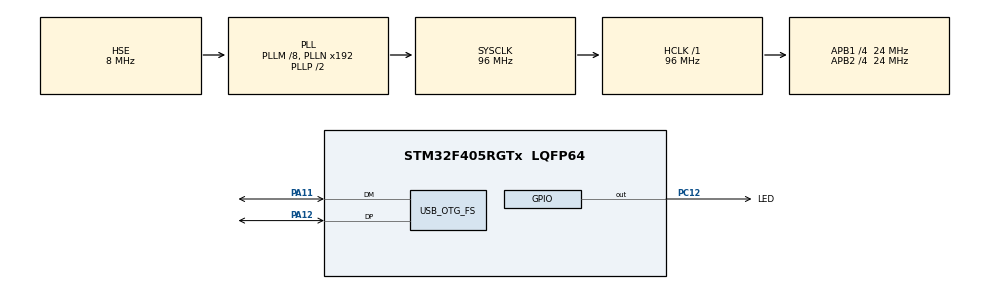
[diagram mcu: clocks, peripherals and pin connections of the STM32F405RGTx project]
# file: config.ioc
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IWDG.Prescaler=IWDG_PRESCALER_32
Mcu.Family=STM32F4
Mcu.Name=STM32F405RGTx
Mcu.Package=LQFP64
NVIC.OTG_FS_IRQn=true\:0\:0\:false
NVIC.PriorityGroup=NVIC_PRIORITYGROUP_4
PA11.Mode=Device_Only
PA11.Signal=USB_OTG_FS_DM
PA12.Mode=Device_Only
PA12.Signal=USB_OTG_FS_DP
PC12.GPIO_Label=LED
PC12.GPIO_ModeDefaultOutputPP=GPIO_MODE_OUTPUT_OD
PC12.GPIO_PuPd=GPIO_NOPULL
PC12.GPIO_Speed=GPIO_SPEED_LOW
PC12.Signal=GPIO_Output
PC14-OSC32_IN.Mode=LSE-External-Oscillator
PC14-OSC32_IN.Signal=RCC_OSC32_IN
PC15-OSC32_OUT.Mode=LSE-External-Oscillator
PC15-OSC32_OUT.Signal=RCC_OSC32_OUT
PH0-OSC_IN.Mode=HSE-External-Oscillator
PH0-OSC_IN.Signal=RCC_OSC_IN
PH1-OSC_OUT.Mode=HSE-External-Oscillator
PH1-OSC_OUT.Signal=RCC_OSC_OUT
ProjectManager.TargetToolchain=EWARM
RCC.48MHZClocksFreq_Value=48000000
RCC.AHBFreq_Value=96000000
RCC.APB1CLKDivider=RCC_HCLK_DIV4
RCC.APB1Freq_Value=24000000
RCC.APB1TimFreq_Value=48000000
RCC.APB2CLKDivider=RCC_HCLK_DIV4
RCC.APB2Freq_Value=24000000
RCC.APB2TimFreq_Value=48000000
RCC.CortexFreq_Value=96000000
RCC.HCLKFreq_Value=96000000
RCC.HSE_VALUE=8000000
RCC.HSI_VALUE=16000000
RCC.PLLM=8
RCC.SYSCLKFreq_VALUE=96000000
RCC.SYSCLKSource=RCC_SYSCLKSOURCE_PLLCLK
RCC.VCOOutputFreq_Value=192000000
USB_DEVICE.CLASS_NAME-CDC_FS=CDC
USB_DEVICE.USBD_HandleTypeDef-CDC_FS=hUsbDeviceFS
USB_DEVICE.VirtualMode-CDC_FS=Cdc
USB_DEVICE.VirtualModeFS=Cdc_FS
USB_OTG_FS.VirtualMode=Device_Only
USB_OTG_FS.vbus_sensing_enable=DISABLE
VP_IWDG_VS_IWDG.Mode=IWDG_Activate
VP_USB_DEVICE_VS_USB_DEVICE_CDC_FS.Mode=CDC_FS

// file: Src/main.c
/**
  ******************************************************************************
  * File Name          : main.c
  * Description        : Main program body
  ******************************************************************************
  *
  * COPYRIGHT(c) 2015 STMicroelectronics
  *
  * Redistribution and use in source and binary forms, with or without modification,
  * are permitted provided that the following conditions are met:
  *   1. Redistributions of source code must retain the above copyright notice,
  *      this list of conditions and the following disclaimer.
  *   2. Redistributions in binary form must reproduce the above copyright notice,
  *      this list of conditions and the following disclaimer in the documentation
  *      and/or other materials provided with the distribution.
  *   3. Neither the name of STMicroelectronics nor the names of its contributors
  *      may be used to endorse or promote products derived from this software
  *      without specific prior written permission.
  *
  * THIS SOFTWARE IS PROVIDED BY THE COPYRIGHT HOLDERS AND CONTRIBUTORS "AS IS"
  * AND ANY EXPRESS OR IMPLIED WARRANTIES, INCLUDING, BUT NOT LIMITED TO, THE
  * IMPLIED WARRANTIES OF MERCHANTABILITY AND FITNESS FOR A PARTICULAR PURPOSE ARE
  * DISCLAIMED. IN NO EVENT SHALL THE COPYRIGHT HOLDER OR CONTRIBUTORS BE LIABLE
  * FOR ANY DIRECT, INDIRECT, INCIDENTAL, SPECIAL, EXEMPLARY, OR CONSEQUENTIAL
  * DAMAGES (INCLUDING, BUT NOT LIMITED TO, PROCUREMENT OF SUBSTITUTE GOODS OR
  * SERVICES; LOSS OF USE, DATA, OR PROFITS; OR BUSINESS INTERRUPTION) HOWEVER
  * CAUSED AND ON ANY THEORY OF LIABILITY, WHETHER IN CONTRACT, STRICT LIABILITY,
  * OR TORT (INCLUDING NEGLIGENCE OR OTHERWISE) ARISING IN ANY WAY OUT OF THE USE
  * OF THIS SOFTWARE, EVEN IF ADVISED OF THE POSSIBILITY OF SUCH DAMAGE.
  *
  ******************************************************************************
  */

#include "stm32f4xx_hal.h"
#include "usb_device.h"

/* USER CODE BEGIN Includes */
#include "main.h"
#include "cli.h"
#include "config.h"
/* USER CODE END Includes */

IWDG_HandleTypeDef hiwdg;

void SystemClock_Config(void);
static void MX_GPIO_Init(void);
static void MX_IWDG_Init(void);

int main(void)
{

  /* MCU Configuration----------------------------------------------------------*/

  /* Reset of all peripherals, Initializes the Flash interface and the Systick. */
  HAL_Init();

  /* Configure the system clock */
  SystemClock_Config();

  /* Initialize all configured peripherals */
  MX_GPIO_Init();
  MX_IWDG_Init();
  MX_USB_DEVICE_Init();

  /* USER CODE BEGIN 2 */
	cfg_init();
  /* USER CODE END 2 */

  /* Infinite loop */
  while (1)
  {

  /* USER CODE BEGIN 3 */
    cli_run();

  }
  /* USER CODE END 3 */

}

/** System Clock Configuration
*/
void SystemClock_Config(void)
{

  RCC_OscInitTypeDef RCC_OscInitStruct;
  RCC_ClkInitTypeDef RCC_ClkInitStruct;

  __PWR_CLK_ENABLE();

  __HAL_PWR_VOLTAGESCALING_CONFIG(PWR_REGULATOR_VOLTAGE_SCALE2);

  RCC_OscInitStruct.OscillatorType = RCC_OSCILLATORTYPE_LSI|RCC_OSCILLATORTYPE_HSE;
  RCC_OscInitStruct.HSEState = RCC_HSE_ON;
  RCC_OscInitStruct.LSIState = RCC_LSI_ON;
  RCC_OscInitStruct.PLL.PLLState = RCC_PLL_ON;
  RCC_OscInitStruct.PLL.PLLSource = RCC_PLLSOURCE_HSE;
  RCC_OscInitStruct.PLL.PLLM = 8;
  RCC_OscInitStruct.PLL.PLLN = 192;
  RCC_OscInitStruct.PLL.PLLP = RCC_PLLP_DIV2;
  RCC_OscInitStruct.PLL.PLLQ = 4;
  HAL_RCC_OscConfig(&RCC_OscInitStruct);

  RCC_ClkInitStruct.ClockType = RCC_CLOCKTYPE_SYSCLK|RCC_CLOCKTYPE_PCLK1
                              |RCC_CLOCKTYPE_PCLK2;
  RCC_ClkInitStruct.SYSCLKSource = RCC_SYSCLKSOURCE_PLLCLK;
  RCC_ClkInitStruct.AHBCLKDivider = RCC_SYSCLK_DIV1;
  RCC_ClkInitStruct.APB1CLKDivider = RCC_HCLK_DIV4;
  RCC_ClkInitStruct.APB2CLKDivider = RCC_HCLK_DIV4;
  HAL_RCC_ClockConfig(&RCC_ClkInitStruct, FLASH_LATENCY_3);

  HAL_SYSTICK_Config(HAL_RCC_GetHCLKFreq()/1000);

  HAL_SYSTICK_CLKSourceConfig(SYSTICK_CLKSOURCE_HCLK);

}

/* IWDG init function */
void MX_IWDG_Init(void)
{

  hiwdg.Instance = IWDG;
  hiwdg.Init.Prescaler = IWDG_PRESCALER_32;
  hiwdg.Init.Reload = 4095;
  HAL_IWDG_Init(&hiwdg);

}

/** Configure pins as
        * Analog
        * Input
        * Output
        * EVENT_OUT
        * EXTI
*/
void MX_GPIO_Init(void)
{

  GPIO_InitTypeDef GPIO_InitStruct;

  /* GPIO Ports Clock Enable */
  __GPIOC_CLK_ENABLE();
  __GPIOH_CLK_ENABLE();
  __GPIOA_CLK_ENABLE();

  /*Configure GPIO pin : PC12 */
  GPIO_InitStruct.Pin = GPIO_PIN_12;
  GPIO_InitStruct.Mode = GPIO_MODE_OUTPUT_OD;
  GPIO_InitStruct.Pull = GPIO_NOPULL;
  GPIO_InitStruct.Speed = GPIO_SPEED_LOW;
  HAL_GPIO_Init(GPIOC, &GPIO_InitStruct);

}

/* USER CODE BEGIN 4 */

void LED_On(void)
{
  HAL_GPIO_WritePin(LED_PORT, LED_PIN, GPIO_PIN_RESET);
}

void LED_Off(void)
{
  HAL_GPIO_WritePin(LED_PORT, LED_PIN, GPIO_PIN_SET);
}

void LED_Toggle(void)
{
  HAL_GPIO_TogglePin(LED_PORT, LED_PIN);
}

#ifdef USE_FULL_ASSERT
void assertion_failed(const char* file, unsigned line)
{
	assert_failed((uint8_t*)file, line);
}
#endif

/* USER CODE END 4 */

#ifdef USE_FULL_ASSERT

/**
   * @brief Reports the name of the source file and the source line number
   * where the assert_param error has occurred.
   * @param file: pointer to the source file name
   * @param line: assert_param error line source number
   * @retval None
   */
void assert_failed(uint8_t* file, uint32_t line)
{
  /* USER CODE BEGIN 6 */
  /* User can add his own implementation to report the file name and line number,
    ex: printf("Wrong parameters value: file %s on line %d\r\n", file, line) */
  MX_IWDG_Init();
  for (;;) {
	  /* Fast blinking LED */
    __HAL_IWDG_RELOAD_COUNTER(&hiwdg);
    LED_Toggle();
	  HAL_Delay(70);
  }
  /* USER CODE END 6 */

}

#endif

/************************ (C) COPYRIGHT STMicroelectronics *****END OF FILE****/
